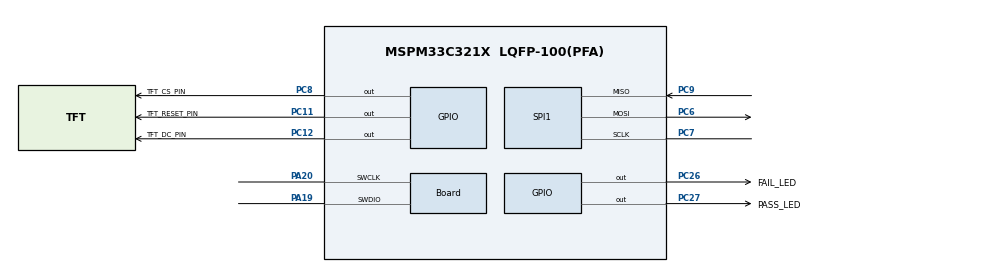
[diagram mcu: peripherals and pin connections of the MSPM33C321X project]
/**
 * @cliArgs --device "MSPM33C321X" --part "Default" --package "LQFP-100(PFA)" --product "mspm33_sdk@1.00.00.00"
 * @versions {"tool":"1.25.0+4268"}
 */

/**
 * Import the modules used in this configuration.
 */
const GPIO   = scripting.addModule("/ti/driverlib/GPIO", {}, false);
const GPIO1  = GPIO.addInstance();
const GPIO2  = GPIO.addInstance();
const GPIO3  = GPIO.addInstance();
const GPIO4  = GPIO.addInstance();
const SPI    = scripting.addModule("/ti/driverlib/SPI", {}, false);
const SPI1   = SPI.addInstance();
const SYSCTL = scripting.addModule("/ti/driverlib/SYSCTL");

/**
 * Write custom configuration values to the imported modules.
 */
GPIO1.$name                                 = "GPIO_LEDS";
GPIO1.associatedPins.create(2);
GPIO1.associatedPins[0].$name               = "FAIL_LED";
GPIO1.associatedPins[0].assignedPort        = "PORTC";
GPIO1.associatedPins[0].assignedPortSegment = "Upper";
GPIO1.associatedPins[0].assignedPin         = "26";
GPIO1.associatedPins[0].launchPadShortcut   = "LED2RedEn";
GPIO1.associatedPins[0].pin.$assign         = "PC26";
GPIO1.associatedPins[1].$name               = "PASS_LED";
GPIO1.associatedPins[1].launchPadShortcut   = "LED2GreenEn";
GPIO1.associatedPins[1].pin.$assign         = "PC27";

const Board                       = scripting.addModule("/ti/driverlib/Board", {}, false);
Board.peripheral.$assign          = "DEBUGSS";
Board.peripheral.swclkPin.$assign = "PA20";
Board.peripheral.swdioPin.$assign = "PA19";

GPIO2.$name                                 = "GPIO_TFT_CS";
GPIO2.associatedPins[0].$name               = "TFT_CS_PIN";
GPIO2.associatedPins[0].assignedPort        = "PORTC";
GPIO2.associatedPins[0].assignedPortSegment = "Lower";
GPIO2.associatedPins[0].assignedPin         = "8";
GPIO2.associatedPins[0].pin.$assign         = "PC8";

GPIO3.$name                                 = "GPIO_TFT_DC";
GPIO3.associatedPins[0].$name               = "TFT_DC_PIN";
GPIO3.associatedPins[0].assignedPort        = "PORTC";
GPIO3.associatedPins[0].assignedPortSegment = "Lower";
GPIO3.associatedPins[0].assignedPin         = "12";
GPIO3.associatedPins[0].pin.$assign         = "PC12";

GPIO4.$name                                 = "GPIO_TFT_RESET";
GPIO4.associatedPins[0].$name               = "TFT_RESET_PIN";
GPIO4.associatedPins[0].assignedPort        = "PORTC";
GPIO4.associatedPins[0].assignedPortSegment = "Lower";
GPIO4.associatedPins[0].assignedPin         = "11";
GPIO4.associatedPins[0].pin.$assign         = "PC11";

SPI1.$name                              = "SPI_1";
SPI1.peripheral.sclkPin.$assign         = "PC7";
SPI1.peripheral.mosiPin.$assign         = "PC6";
SPI1.peripheral.misoPin.$assign         = "PC9";
SPI1.sclkPinConfig.direction            = scripting.forceWrite("OUTPUT");
SPI1.sclkPinConfig.onlyInternalResistor = scripting.forceWrite(false);
SPI1.sclkPinConfig.passedPeripheralType = scripting.forceWrite("Digital");
SPI1.sclkPinConfig.$name                = "ti_driverlib_gpio_GPIOPinGeneric4";
SPI1.mosiPinConfig.direction            = scripting.forceWrite("OUTPUT");
SPI1.mosiPinConfig.hideOutputInversion  = scripting.forceWrite(false);
SPI1.mosiPinConfig.onlyInternalResistor = scripting.forceWrite(false);
SPI1.mosiPinConfig.passedPeripheralType = scripting.forceWrite("Digital");
SPI1.mosiPinConfig.$name                = "ti_driverlib_gpio_GPIOPinGeneric5";
SPI1.misoPinConfig.onlyInternalResistor = scripting.forceWrite(false);
SPI1.misoPinConfig.passedPeripheralType = scripting.forceWrite("Digital");
SPI1.misoPinConfig.$name                = "ti_driverlib_gpio_GPIOPinGeneric6";
SPI1.cs0PinConfig.$name                 = "ti_driverlib_gpio_GPIOPinGeneric3";
SPI1.cs0PinConfig.direction             = scripting.forceWrite("OUTPUT");
SPI1.cs0PinConfig.hideOutputInversion   = scripting.forceWrite(false);
SPI1.cs0PinConfig.onlyInternalResistor  = scripting.forceWrite(false);
SPI1.cs0PinConfig.passedPeripheralType  = scripting.forceWrite("Digital");

SYSCTL.forceDefaultClkConfig = true;
SYSCTL.peripheral.$assign    = "SYSCTL";

/**
 * Pinmux solution for unlocked pins/peripherals. This ensures that minor changes to the automatic solver in a future
 * version of the tool will not impact the pinmux you originally saw.  These lines can be completely deleted in order to
 * re-solve from scratch.
 */
SPI1.peripheral.$suggestSolution        = "UC6";
SPI1.peripheral.cs0Pin.$suggestSolution = "PA12";
